VERSION ""

NS_ :

BS_:

BU_: VCU Inverter4 Inverter3 Inverter2 Inverter1

BO_ 3221225472 VECTOR__INDEPENDENT_SIG_MSG: 0 Vector__XXX
 SG_ Control_Word_FS : 0|16@1- (1,0) [-32768|32767] "" Vector__XXX
 SG_ Control_Word_FS : 0|16@1- (1,0) [-32768|32767] "" Vector__XXX
 SG_ Control_Word_FS : 0|16@1- (1,0) [-32768|32767] "" Vector__XXX
 SG_ Control_Word_FS : 0|16@1- (1,0) [-32768|32767] "" Vector__XXX
 SG_ Status_word : 0|16@1+ (1,0) [0|65535] "" Vector__XXX
 SG_ Status_word : 0|16@1+ (1,0) [0|65535] "" Vector__XXX
 SG_ Status_word : 0|16@1+ (1,0) [0|65535] "" Vector__XXX
 SG_ Status_word : 0|16@1+ (1,0) [0|65535] "" Vector__XXX

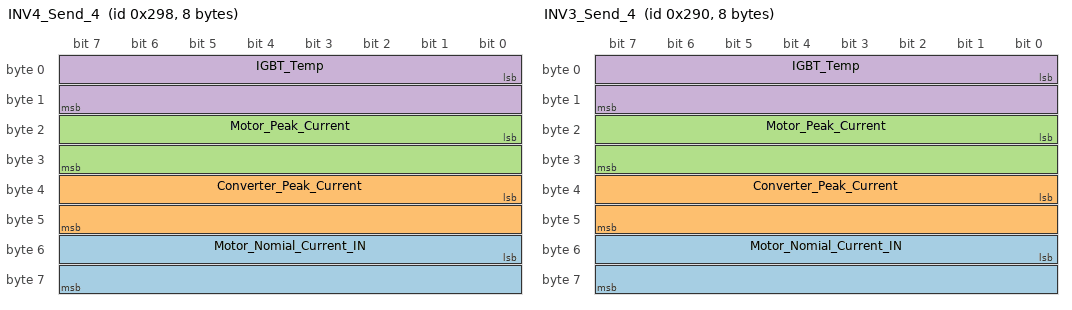
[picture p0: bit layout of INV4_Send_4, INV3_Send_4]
BO_ 664 INV4_Send_4: 8 Inverter4
 SG_ Motor_Nomial_Current_IN : 48|16@1- (1,0) [-32768|32767] "A" Vector__XXX
 SG_ Converter_Peak_Current : 32|16@1- (1,0) [-32768|32767] "A" Vector__XXX
 SG_ Motor_Peak_Current : 16|16@1- (1,0) [-32768|32767] "A" Vector__XXX
 SG_ IGBT_Temp : 0|16@1- (0.1,0) [-3276.8|3276.7] "degree" Vector__XXX

BO_ 656 INV3_Send_4: 8 Inverter3
 SG_ Motor_Nomial_Current_IN : 48|16@1- (1,0) [-32768|32767] "A" Vector__XXX
 SG_ Converter_Peak_Current : 32|16@1- (1,0) [-32768|32767] "A" Vector__XXX
 SG_ Motor_Peak_Current : 16|16@1- (1,0) [-32768|32767] "A" Vector__XXX
 SG_ IGBT_Temp : 0|16@1- (0.1,0) [-3276.8|3276.7] "degree" Vector__XXX

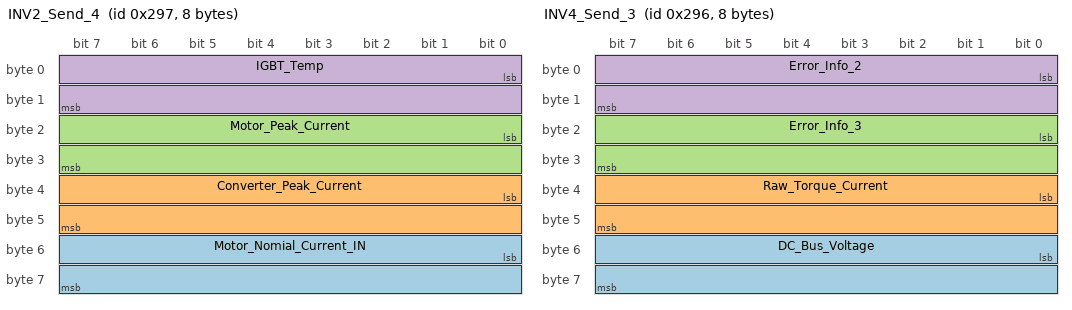
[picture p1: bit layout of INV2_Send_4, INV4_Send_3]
BO_ 663 INV2_Send_4: 8 Inverter2
 SG_ Motor_Nomial_Current_IN : 48|16@1- (1,0) [-32768|32767] "A" Vector__XXX
 SG_ Converter_Peak_Current : 32|16@1- (1,0) [-32768|32767] "A" Vector__XXX
 SG_ Motor_Peak_Current : 16|16@1- (1,0) [-32768|32767] "A" Vector__XXX
 SG_ IGBT_Temp : 0|16@1- (0.1,0) [-3276.8|3276.7] "degree" Vector__XXX

BO_ 662 INV4_Send_3: 8 Inverter4
 SG_ DC_Bus_Voltage : 48|16@1- (1,0) [-32768|32767] "V" Vector__XXX
 SG_ Raw_Torque_Current : 32|16@1- (1,0) [-32768|32767] "A" Vector__XXX
 SG_ Error_Info_3 : 16|16@1- (1,0) [-32768|32767] "" Vector__XXX
 SG_ Error_Info_2 : 0|16@1- (1,0) [-32768|32767] "" Vector__XXX

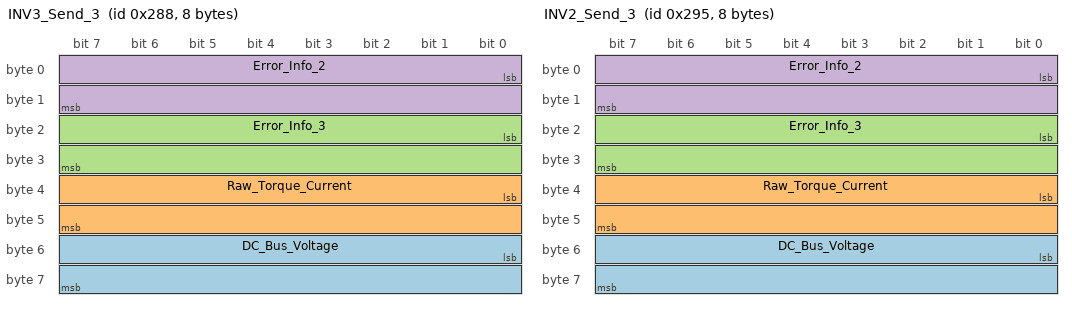
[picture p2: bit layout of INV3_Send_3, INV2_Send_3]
BO_ 648 INV3_Send_3: 8 Inverter3
 SG_ DC_Bus_Voltage : 48|16@1- (1,0) [-32768|32767] "V" Vector__XXX
 SG_ Raw_Torque_Current : 32|16@1- (1,0) [-32768|32767] "A" Vector__XXX
 SG_ Error_Info_3 : 16|16@1- (1,0) [-32768|32767] "" Vector__XXX
 SG_ Error_Info_2 : 0|16@1- (1,0) [-32768|32767] "" Vector__XXX

BO_ 661 INV2_Send_3: 8 Inverter2
 SG_ DC_Bus_Voltage : 48|16@1- (1,0) [-32768|32767] "V" Vector__XXX
 SG_ Raw_Torque_Current : 32|16@1- (1,0) [-32768|32767] "A" Vector__XXX
 SG_ Error_Info_3 : 16|16@1- (1,0) [-32768|32767] "" Vector__XXX
 SG_ Error_Info_2 : 0|16@1- (1,0) [-32768|32767] "" Vector__XXX

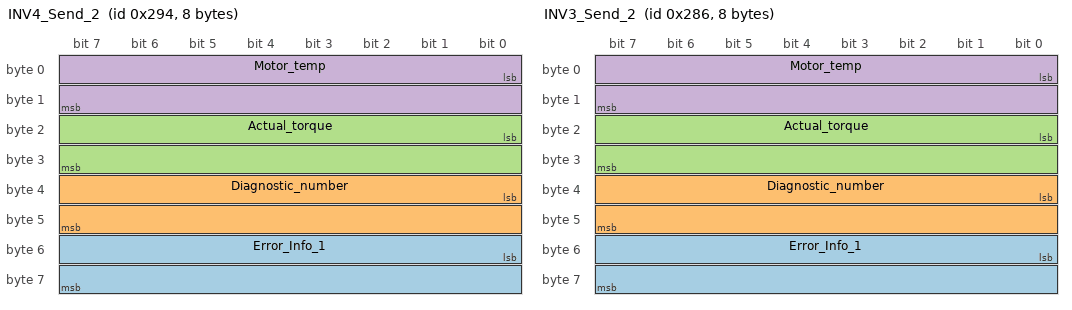
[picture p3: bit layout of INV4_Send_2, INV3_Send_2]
BO_ 660 INV4_Send_2: 8 Inverter4
 SG_ Error_Info_1 : 48|16@1- (1,0) [-32768|32767] "" Vector__XXX
 SG_ Diagnostic_number : 32|16@1- (1,0) [-32768|32767] "" Vector__XXX
 SG_ Actual_torque : 16|16@1- (1,0) [-32768|32767] "" Vector__XXX
 SG_ Motor_temp : 0|16@1- (0.1,0) [-3276.8|3276.7] "degrees" Vector__XXX

BO_ 646 INV3_Send_2: 8 Inverter3
 SG_ Error_Info_1 : 48|16@1- (1,0) [-32768|32767] "" Vector__XXX
 SG_ Diagnostic_number : 32|16@1- (1,0) [-32768|32767] "" Vector__XXX
 SG_ Actual_torque : 16|16@1- (1,0) [-32768|32767] "" Vector__XXX
 SG_ Motor_temp : 0|16@1- (0.1,0) [-3276.8|3276.7] "degrees" Vector__XXX

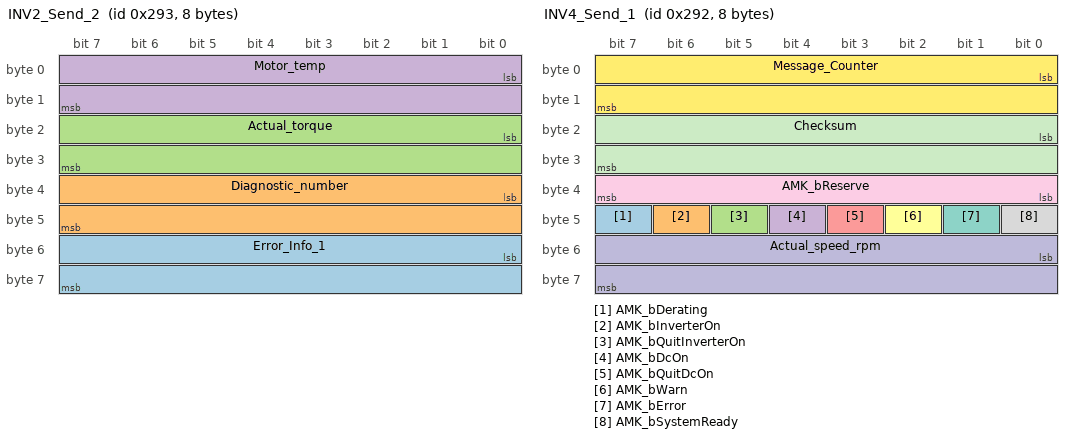
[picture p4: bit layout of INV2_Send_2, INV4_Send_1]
BO_ 659 INV2_Send_2: 8 Inverter2
 SG_ Error_Info_1 : 48|16@1- (1,0) [-32768|32767] "" Vector__XXX
 SG_ Diagnostic_number : 32|16@1- (1,0) [-32768|32767] "" Vector__XXX
 SG_ Actual_torque : 16|16@1- (1,0) [-32768|32767] "" Vector__XXX
 SG_ Motor_temp : 0|16@1- (0.1,0) [-3276.8|3276.7] "degrees" Vector__XXX

BO_ 658 INV4_Send_1: 8 Inverter4
 SG_ AMK_bDerating : 47|1@1+ (1,0) [0|1] "" Vector__XXX
 SG_ AMK_bInverterOn : 46|1@1+ (1,0) [0|1] "" Vector__XXX
 SG_ AMK_bQuitInverterOn : 45|1@1+ (1,0) [0|1] "" Vector__XXX
 SG_ AMK_bDcOn : 44|1@1+ (1,0) [0|255] "" Vector__XXX
 SG_ AMK_bQuitDcOn : 43|1@1+ (1,0) [0|1] "" Vector__XXX
 SG_ AMK_bWarn : 42|1@1+ (1,0) [0|1] "" Vector__XXX
 SG_ AMK_bError : 41|1@1+ (1,0) [0|1] "" Vector__XXX
 SG_ AMK_bSystemReady : 40|1@1+ (1,0) [0|1] "" Vector__XXX
 SG_ AMK_bReserve : 32|8@1- (1,0) [-128|127] "" Vector__XXX
 SG_ Actual_speed_rpm : 48|16@1- (1,0) [-32768|32767] "rpm" Vector__XXX
 SG_ Checksum : 16|16@1+ (1,0) [0|65535] "" Vector__XXX
 SG_ Message_Counter : 0|16@1+ (1,0) [0|65535] "" Vector__XXX

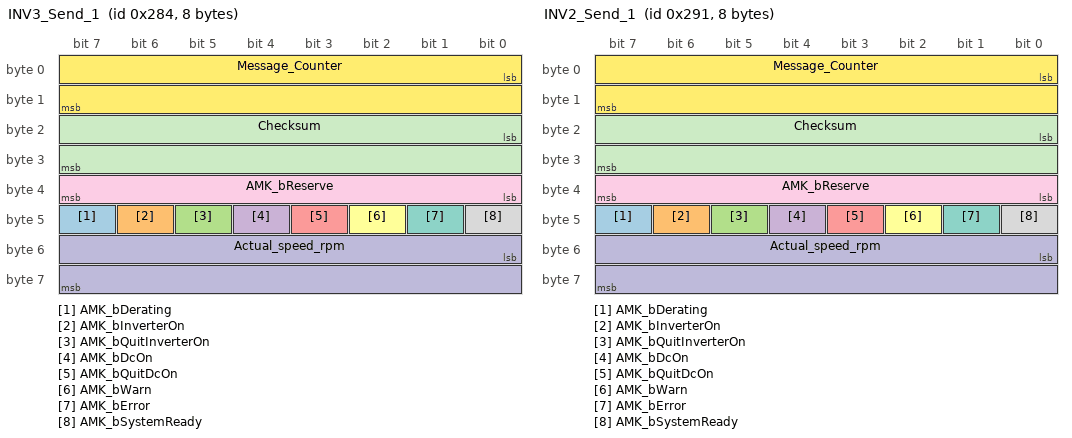
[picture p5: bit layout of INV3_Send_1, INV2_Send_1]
BO_ 644 INV3_Send_1: 8 Inverter3
 SG_ AMK_bDerating : 47|1@1+ (1,0) [0|1] "" Vector__XXX
 SG_ AMK_bInverterOn : 46|1@1+ (1,0) [0|1] "" Vector__XXX
 SG_ AMK_bQuitInverterOn : 45|1@1+ (1,0) [0|1] "" Vector__XXX
 SG_ AMK_bDcOn : 44|1@1+ (1,0) [0|255] "" Vector__XXX
 SG_ AMK_bQuitDcOn : 43|1@1+ (1,0) [0|1] "" Vector__XXX
 SG_ AMK_bWarn : 42|1@1+ (1,0) [0|1] "" Vector__XXX
 SG_ AMK_bError : 41|1@1+ (1,0) [0|1] "" Vector__XXX
 SG_ AMK_bSystemReady : 40|1@1+ (1,0) [0|1] "" Vector__XXX
 SG_ AMK_bReserve : 32|8@1- (1,0) [-128|127] "" Vector__XXX
 SG_ Actual_speed_rpm : 48|16@1- (1,0) [-32768|32767] "rpm" Vector__XXX
 SG_ Checksum : 16|16@1+ (1,0) [0|65535] "" Vector__XXX
 SG_ Message_Counter : 0|16@1+ (1,0) [0|65535] "" Vector__XXX

BO_ 657 INV2_Send_1: 8 Inverter2
 SG_ AMK_bDerating : 47|1@1+ (1,0) [0|1] "" Vector__XXX
 SG_ AMK_bInverterOn : 46|1@1+ (1,0) [0|1] "" Vector__XXX
 SG_ AMK_bQuitInverterOn : 45|1@1+ (1,0) [0|1] "" Vector__XXX
 SG_ AMK_bDcOn : 44|1@1+ (1,0) [0|255] "" Vector__XXX
 SG_ AMK_bQuitDcOn : 43|1@1+ (1,0) [0|1] "" Vector__XXX
 SG_ AMK_bWarn : 42|1@1+ (1,0) [0|1] "" Vector__XXX
 SG_ AMK_bError : 41|1@1+ (1,0) [0|1] "" Vector__XXX
 SG_ AMK_bSystemReady : 40|1@1+ (1,0) [0|1] "" Vector__XXX
 SG_ AMK_bReserve : 32|8@1- (1,0) [-128|127] "" Vector__XXX
 SG_ Actual_speed_rpm : 48|16@1- (1,0) [-32768|32767] "rpm" Vector__XXX
 SG_ Checksum : 16|16@1+ (1,0) [0|65535] "" Vector__XXX
 SG_ Message_Counter : 0|16@1+ (1,0) [0|65535] "" Vector__XXX

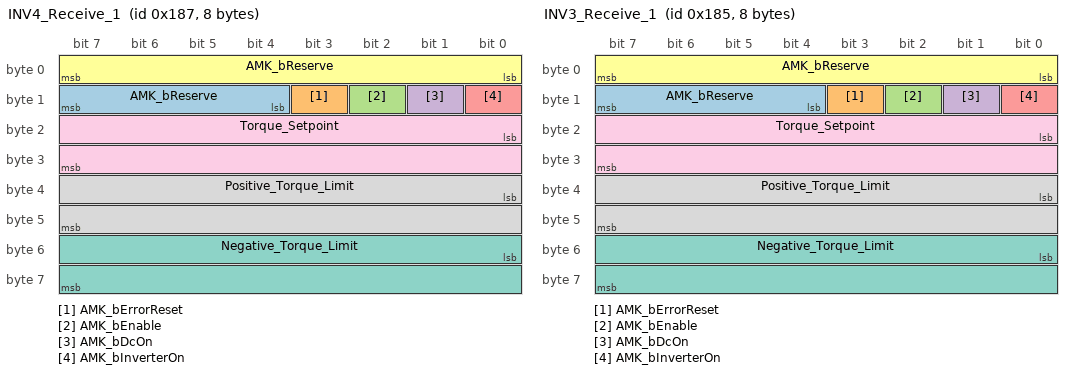
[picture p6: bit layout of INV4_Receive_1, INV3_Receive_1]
BO_ 391 INV4_Receive_1: 8 VCU
 SG_ AMK_bReserve : 12|4@1- (1,0) [-128|127] "" Vector__XXX
 SG_ AMK_bErrorReset : 11|1@1+ (1,0) [0|1] "" Vector__XXX
 SG_ AMK_bEnable : 10|1@1+ (1,0) [0|1] "" Vector__XXX
 SG_ AMK_bDcOn : 9|1@1+ (1,0) [0|1] "" Vector__XXX
 SG_ AMK_bInverterOn : 8|1@1+ (1,0) [0|1] "" Vector__XXX
 SG_ AMK_bReserve : 0|8@1- (1,0) [-128|127] "" Vector__XXX
 SG_ Negative_Torque_Limit : 48|16@1- (0.1,0) [-3276.8|3276.7] "rpm" Vector__XXX
 SG_ Positive_Torque_Limit : 32|16@1- (0.1,0) [-3276.8|3276.7] "rpm" Vector__XXX
 SG_ Torque_Setpoint : 16|16@1- (0.1,0) [-3276.8|3276.7] "" Vector__XXX

BO_ 389 INV3_Receive_1: 8 VCU
 SG_ AMK_bReserve : 12|4@1- (1,0) [-128|127] "" Vector__XXX
 SG_ AMK_bErrorReset : 11|1@1+ (1,0) [0|1] "" Vector__XXX
 SG_ AMK_bEnable : 10|1@1+ (1,0) [0|1] "" Vector__XXX
 SG_ AMK_bDcOn : 9|1@1+ (1,0) [0|1] "" Vector__XXX
 SG_ AMK_bInverterOn : 8|1@1+ (1,0) [0|1] "" Vector__XXX
 SG_ AMK_bReserve : 0|8@1- (1,0) [-128|127] "" Vector__XXX
 SG_ Negative_Torque_Limit : 48|16@1- (0.1,0) [-3276.8|3276.7] "rpm" Vector__XXX
 SG_ Positive_Torque_Limit : 32|16@1- (0.1,0) [-3276.8|3276.7] "rpm" Vector__XXX
 SG_ Torque_Setpoint : 16|16@1- (0.1,0) [-3276.8|3276.7] "" Vector__XXX

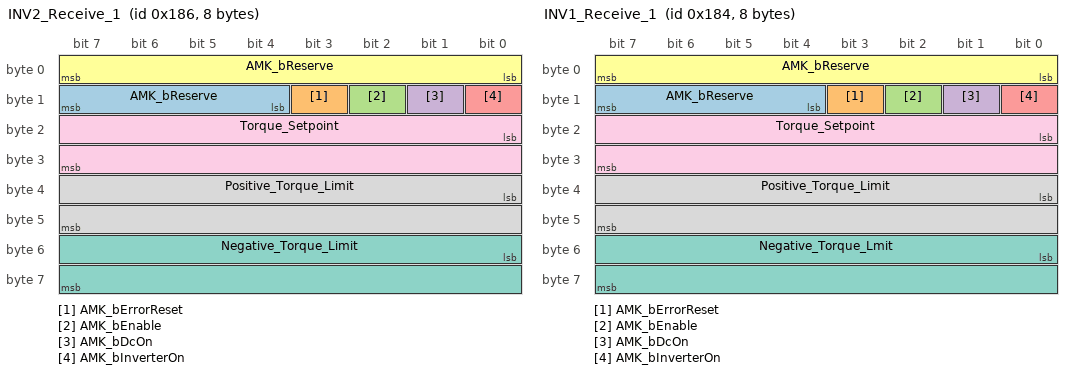
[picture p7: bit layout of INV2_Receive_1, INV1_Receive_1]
BO_ 390 INV2_Receive_1: 8 VCU
 SG_ AMK_bReserve : 12|4@1- (1,0) [-128|127] "" Vector__XXX
 SG_ AMK_bErrorReset : 11|1@1+ (1,0) [0|1] "" Vector__XXX
 SG_ AMK_bEnable : 10|1@1+ (1,0) [0|1] "" Vector__XXX
 SG_ AMK_bDcOn : 9|1@1+ (1,0) [0|1] "" Vector__XXX
 SG_ AMK_bInverterOn : 8|1@1+ (1,0) [0|1] "" Vector__XXX
 SG_ AMK_bReserve : 0|8@1- (1,0) [-128|127] "" Vector__XXX
 SG_ Negative_Torque_Limit : 48|16@1- (0.1,0) [-3276.8|3276.7] "rpm" Vector__XXX
 SG_ Positive_Torque_Limit : 32|16@1- (0.1,0) [-3276.8|3276.7] "" Vector__XXX
 SG_ Torque_Setpoint : 16|16@1- (0.1,0) [-3276.8|3276.7] "" Vector__XXX

BO_ 388 INV1_Receive_1: 8 VCU
 SG_ AMK_bReserve : 12|4@1- (1,0) [-128|127] "" Vector__XXX
 SG_ AMK_bErrorReset : 11|1@1+ (1,0) [0|1] "" Vector__XXX
 SG_ AMK_bEnable : 10|1@1+ (1,0) [0|1] "" Vector__XXX
 SG_ AMK_bDcOn : 9|1@1+ (1,0) [0|1] "" Vector__XXX
 SG_ AMK_bInverterOn : 8|1@1+ (1,0) [0|1] "" Vector__XXX
 SG_ AMK_bReserve : 0|8@1- (1,0) [-128|127] "" Vector__XXX
 SG_ Negative_Torque_Lmit : 48|16@1- (0.1,0) [-3276.8|3276.7] "" Vector__XXX
 SG_ Positive_Torque_Limit : 32|16@1- (0.1,0) [-3276.8|3276.7] "" Vector__XXX
 SG_ Torque_Setpoint : 16|16@1- (0.1,0) [-3276.8|3276.7] "" Vector__XXX

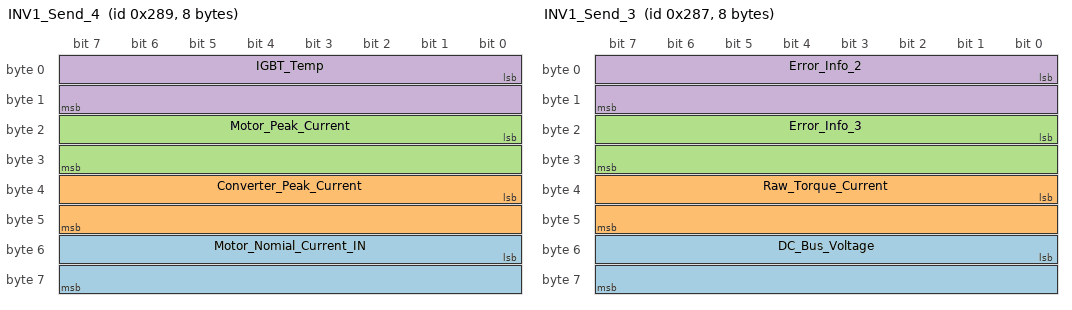
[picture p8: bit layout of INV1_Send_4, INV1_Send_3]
BO_ 649 INV1_Send_4: 8 Inverter1
 SG_ Motor_Nomial_Current_IN : 48|16@1- (1,0) [-32768|32767] "A" Vector__XXX
 SG_ Converter_Peak_Current : 32|16@1- (1,0) [-32768|32767] "A" Vector__XXX
 SG_ Motor_Peak_Current : 16|16@1- (1,0) [-32768|32767] "A" Vector__XXX
 SG_ IGBT_Temp : 0|16@1- (0.1,0) [-3276.8|3276.7] "degree" Vector__XXX

BO_ 647 INV1_Send_3: 8 Inverter1
 SG_ DC_Bus_Voltage : 48|16@1- (1,0) [-32768|32767] "V" Vector__XXX
 SG_ Raw_Torque_Current : 32|16@1- (1,0) [-32768|32767] "A" Vector__XXX
 SG_ Error_Info_3 : 16|16@1- (1,0) [-32768|32767] "" Vector__XXX
 SG_ Error_Info_2 : 0|16@1- (1,0) [-32768|32767] "" Vector__XXX

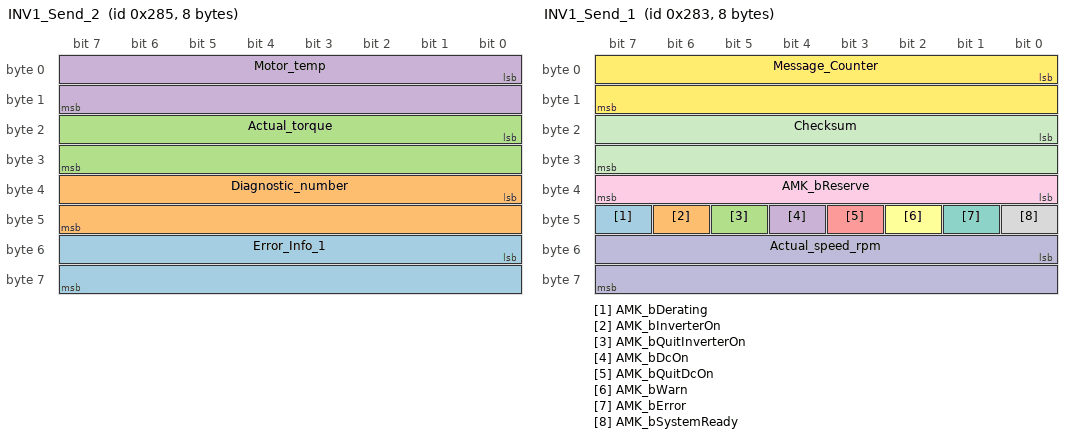
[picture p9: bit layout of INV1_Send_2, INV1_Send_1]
BO_ 645 INV1_Send_2: 8 Inverter1
 SG_ Error_Info_1 : 48|16@1- (1,0) [-32768|32767] "" Vector__XXX
 SG_ Diagnostic_number : 32|16@1- (1,0) [-32768|32767] "" Vector__XXX
 SG_ Actual_torque : 16|16@1- (1,0) [-32768|32767] "" Vector__XXX
 SG_ Motor_temp : 0|16@1- (0.1,0) [-3276.8|3276.7] "degrees" Vector__XXX

BO_ 643 INV1_Send_1: 8 Inverter1
 SG_ AMK_bDerating : 47|1@1+ (1,0) [0|1] "" Vector__XXX
 SG_ AMK_bInverterOn : 46|1@1+ (1,0) [0|1] "" Vector__XXX
 SG_ AMK_bQuitInverterOn : 45|1@1+ (1,0) [0|1] "" Vector__XXX
 SG_ AMK_bDcOn : 44|1@1+ (1,0) [0|255] "" Vector__XXX
 SG_ AMK_bQuitDcOn : 43|1@1+ (1,0) [0|1] "" Vector__XXX
 SG_ AMK_bWarn : 42|1@1+ (1,0) [0|1] "" Vector__XXX
 SG_ AMK_bError : 41|1@1+ (1,0) [0|1] "" Vector__XXX
 SG_ AMK_bSystemReady : 40|1@1+ (1,0) [0|1] "" Vector__XXX
 SG_ AMK_bReserve : 32|8@1- (1,0) [-128|127] "" Vector__XXX
 SG_ Actual_speed_rpm : 48|16@1- (1,0) [-32768|32767] "rpm" Vector__XXX
 SG_ Checksum : 16|16@1+ (1,0) [0|65535] "" Vector__XXX
 SG_ Message_Counter : 0|16@1+ (1,0) [0|65535] "" Vector__XXX

CM_ BO_ 3221225472 "This is a message for not used signals, created by Vector CANdb++ DBC OLE DB Provider.";
BA_DEF_  "BusType" STRING ;
BA_DEF_DEF_  "BusType" "CAN";
